AUTOSAR XML (schema 00048)
package /HuaweiMDC/FunctionalSoftware/SammManage/Execution
  executable SammManageExecutable
    root sw component prototype SammManageRootSwComponent: application-type=SammManageApplicationSwComponent
package /HuaweiMDC/FunctionalSoftware/SammManage/SwComponent
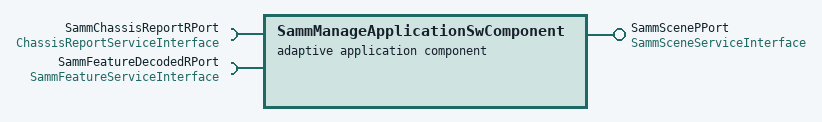
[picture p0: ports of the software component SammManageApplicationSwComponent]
  adaptive application sw component type SammManageApplicationSwComponent
    require port SammChassisReportRPort: required-interface=ChassisReportServiceInterface
    require port SammFeatureDecodedRPort: required-interface=SammFeatureServiceInterface
    provide port SammScenePPort: provided-interface=SammSceneServiceInterface
